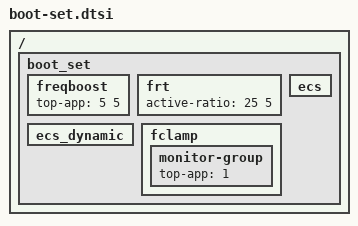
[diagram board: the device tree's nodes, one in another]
/ {
	/* booting exclusive set */
	boot_set: boot_set {
		/* Boosting margin applied to frequency selection */
		freqboost {			/* LIT BIG */
			top-app			= <  5 5>;
		};

		frt {	   			/* LIT BIG */
			active-ratio 		= < 25 5>;
		};

		ecs { };

		ecs_dynamic { };

		fclamp {
			monitor-group {
				top-app         = <1>;
			};
		};
	};
};
